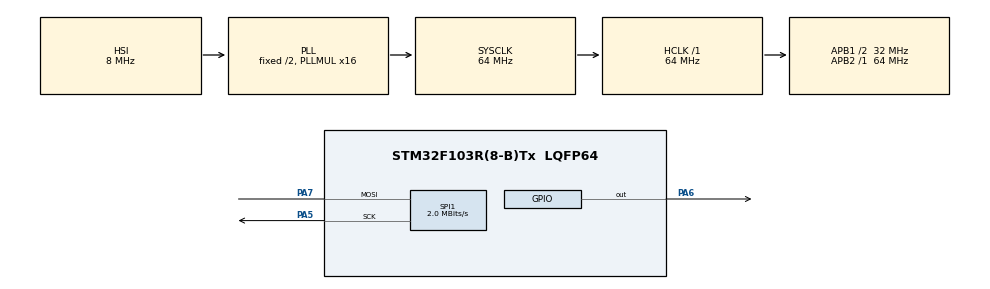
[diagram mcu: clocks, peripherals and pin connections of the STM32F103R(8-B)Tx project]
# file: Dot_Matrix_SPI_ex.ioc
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Mcu.Family=STM32F1
Mcu.Name=STM32F103R(8-B)Tx
Mcu.Package=LQFP64
NVIC.PriorityGroup=NVIC_PRIORITYGROUP_4
PA5.Mode=Simplex_Bidirectional_Master
PA5.Signal=SPI1_SCK
PA6.Signal=GPIO_Output
PA7.Mode=Simplex_Bidirectional_Master
PA7.Signal=SPI1_MOSI
ProjectManager.HeapSize=0x200
ProjectManager.StackSize=0x400
ProjectManager.TargetToolchain=CMake
RCC.AHBFreq_Value=64000000
RCC.APB1CLKDivider=RCC_HCLK_DIV2
RCC.APB1Freq_Value=32000000
RCC.APB1TimFreq_Value=64000000
RCC.APB2Freq_Value=64000000
RCC.APB2TimFreq_Value=64000000
RCC.HCLKFreq_Value=64000000
RCC.PLLMUL=RCC_PLL_MUL16
RCC.SYSCLKFreq_VALUE=64000000
RCC.SYSCLKSource=RCC_SYSCLKSOURCE_PLLCLK
RCC.USBFreq_Value=64000000
SPI1.BaudRatePrescaler=SPI_BAUDRATEPRESCALER_32
SPI1.CLKPolarity=SPI_POLARITY_HIGH
SPI1.CRCCalculation=SPI_CRCCALCULATION_DISABLE
SPI1.CalculateBaudRate=2.0 MBits/s
SPI1.DataSize=SPI_DATASIZE_16BIT
SPI1.Direction=SPI_DIRECTION_1LINE
SPI1.Mode=SPI_MODE_MASTER
SPI1.VirtualType=VM_MASTER
VP_SYS_VS_ND.Mode=No_Debug
board=custom

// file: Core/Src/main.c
/* USER CODE BEGIN Header */
/**
 ******************************************************************************
 * @file           : main.c
 * @brief          : Main program body
 ******************************************************************************
 * @attention
 *
 * Copyright (c) 2025 STMicroelectronics.
 * All rights reserved.
 *
 * This software is licensed under terms that can be found in the LICENSE file
 * in the root directory of this software component.
 * If no LICENSE file comes with this software, it is provided AS-IS.
 *
 ******************************************************************************
 */
/* USER CODE END Header */
#include "main.h"

/* USER CODE BEGIN Includes */
#include "matrix.h"
/* USER CODE END Includes */

SPI_HandleTypeDef hspi1;

void SystemClock_Config(void);
static void MX_GPIO_Init(void);
static void MX_SPI1_Init(void);

int main(void) {

    /* MCU
     * Configuration--------------------------------------------------------*/

    /* Reset of all peripherals, Initializes the Flash interface and the
     * Systick. */
    HAL_Init();

    /* Configure the system clock */
    SystemClock_Config();

    /* Initialize all configured peripherals */
    MX_GPIO_Init();
    MX_SPI1_Init();
    /* USER CODE BEGIN 2 */
    /**
     * MAX7219의 레지스터
     * - Shutdown reg.
     * - Mode reg.
     * - Intensity reg.
     * - Scan reg.
     * - Display-test reg.
     * ------------------------------------------------------------
     * On initial power-up, all control registers are reset, the
     * display is blanked, and the MAX7219/MAX7221 enter
     * shutdown mode. Program the display driver prior to
     * display use. Otherwise, it will initially be set to scan one
     * digit, it will not decode data in the data registers, and
     * the intensity register will be set to its minimum value.
     * ------------------------------------------------------------
     * 1. 파워가 연결되면 모든 레지스터(위에 적은 것들)가 초기화 된다.
     * 2. 먼저 셧다운 모드로 설정된다.
     * 3. 1개의 digit만 스캔하는 모드로 설정된다.
     * 4. 밝기 레지스터도 최소로 설정된다.
     * ------------------------------------------------------------
     * When no-decode is selected, data bits D7–D0 correspond to
     *  the segment lines of the MAX7219/MAX7221.
     * Table 6 shows the one-to-one pairing of each data bit
     * to the appropriate segment line.
     * ------------------------------------------------------------
     * 문서가 8-digit LED에 맞추어 작성되어 있다.
     * Table.5를 참고하면, D7~D0과 SegA~SegG핀의 값에 따라 7-segment의
     *  어떤 LED가 켜지는지 알 수 있다. 본래 기능대로라면 Digit Driver에서
     *  LED가 나타낼 정수값이, Segment Driver에서는 그 정수값을 표현하기
     *  위해 어떤 Segment가 켜지는지 출력된다.
     * 8x8 매트릭스를 위해서는 no-decode 모드로 설정해야한다.
     * no-decode 모드는 Digit Driver와 Segment Driver에 출력될 값이
     *  DIN(SPI의 MOSI)으로 전달된 데이터값이다. 디코드 되지 않고 곧바로
     *  출력된다.
     * 왜 Digit Driver가 매트릭스의 행이고 Segment Driver가
     *  매트릭스의 열인지 모르겠다. 매트릭스의 데이터 시트에 내용이 부족해
     *  이유를 정확히 알지 못했다.
     * ------------------------------------------------------------
     */
    LED_Matrix_Init(&hspi1);
    /* USER CODE END 2 */

    /* Infinite loop */
    /* USER CODE BEGIN WHILE */
    LED_Matrix_Clear(&hspi1);
    uint8_t matrix[8] = {0b11111111, 0b00000001, 0b00000001, 0b00000001,
                         0b00000001, 0b11110001, 0b00000001, 0b00001111};

    LED_Matrix_Print(&hspi1, matrix);

    while (1) {
        /* USER CODE END WHILE */

    }
}

void SystemClock_Config(void) {
    RCC_OscInitTypeDef RCC_OscInitStruct = {0};
    RCC_ClkInitTypeDef RCC_ClkInitStruct = {0};

    /** Initializes the RCC Oscillators according to the specified parameters
     * in the RCC_OscInitTypeDef structure.
     */
    RCC_OscInitStruct.OscillatorType = RCC_OSCILLATORTYPE_HSI;
    RCC_OscInitStruct.HSIState = RCC_HSI_ON;
    RCC_OscInitStruct.HSICalibrationValue = RCC_HSICALIBRATION_DEFAULT;
    RCC_OscInitStruct.PLL.PLLState = RCC_PLL_ON;
    RCC_OscInitStruct.PLL.PLLSource = RCC_PLLSOURCE_HSI_DIV2;
    RCC_OscInitStruct.PLL.PLLMUL = RCC_PLL_MUL16;
    if (HAL_RCC_OscConfig(&RCC_OscInitStruct) != HAL_OK) {
        Error_Handler();
    }

    /** Initializes the CPU, AHB and APB buses clocks
     */
    RCC_ClkInitStruct.ClockType = RCC_CLOCKTYPE_HCLK | RCC_CLOCKTYPE_SYSCLK |
                                  RCC_CLOCKTYPE_PCLK1 | RCC_CLOCKTYPE_PCLK2;
    RCC_ClkInitStruct.SYSCLKSource = RCC_SYSCLKSOURCE_PLLCLK;
    RCC_ClkInitStruct.AHBCLKDivider = RCC_SYSCLK_DIV1;
    RCC_ClkInitStruct.APB1CLKDivider = RCC_HCLK_DIV2;
    RCC_ClkInitStruct.APB2CLKDivider = RCC_HCLK_DIV1;

    if (HAL_RCC_ClockConfig(&RCC_ClkInitStruct, FLASH_LATENCY_2) != HAL_OK) {
        Error_Handler();
    }
}

static void MX_SPI1_Init(void) {

    /* SPI1 parameter configuration*/
    hspi1.Instance = SPI1;
    hspi1.Init.Mode = SPI_MODE_MASTER;
    hspi1.Init.Direction = SPI_DIRECTION_1LINE;
    hspi1.Init.DataSize = SPI_DATASIZE_16BIT;
    hspi1.Init.CLKPolarity = SPI_POLARITY_HIGH;
    hspi1.Init.CLKPhase = SPI_PHASE_1EDGE;
    hspi1.Init.NSS = SPI_NSS_SOFT;
    hspi1.Init.BaudRatePrescaler = SPI_BAUDRATEPRESCALER_32;
    hspi1.Init.FirstBit = SPI_FIRSTBIT_MSB;
    hspi1.Init.TIMode = SPI_TIMODE_DISABLE;
    hspi1.Init.CRCCalculation = SPI_CRCCALCULATION_DISABLE;
    hspi1.Init.CRCPolynomial = 10;
    if (HAL_SPI_Init(&hspi1) != HAL_OK) {
        Error_Handler();
    }
}

static void MX_GPIO_Init(void) {
    GPIO_InitTypeDef GPIO_InitStruct = {0};

    /* GPIO Ports Clock Enable */
    __HAL_RCC_GPIOA_CLK_ENABLE();

    /*Configure GPIO pin Output Level */
    HAL_GPIO_WritePin(GPIOA, GPIO_PIN_6, GPIO_PIN_RESET);

    /*Configure GPIO pin : PA6 */
    GPIO_InitStruct.Pin = GPIO_PIN_6;
    GPIO_InitStruct.Mode = GPIO_MODE_OUTPUT_PP;
    GPIO_InitStruct.Pull = GPIO_NOPULL;
    GPIO_InitStruct.Speed = GPIO_SPEED_FREQ_LOW;
    HAL_GPIO_Init(GPIOA, &GPIO_InitStruct);

}

void Error_Handler(void) {
    /* USER CODE BEGIN Error_Handler_Debug */
    /* User can add his own implementation to report the HAL error return state
     */
    __disable_irq();
    while (1) {
    }
    /* USER CODE END Error_Handler_Debug */
}

#ifdef USE_FULL_ASSERT
/**
 * @brief  Reports the name of the source file and the source line number
 *         where the assert_param error has occurred.
 * @param  file: pointer to the source file name
 * @param  line: assert_param error line source number
 * @retval None
 */
void assert_failed(uint8_t *file, uint32_t line) {
    /* USER CODE BEGIN 6 */
    /* User can add his own implementation to report the file name and line
       number, ex: printf("Wrong parameters value: file %s on line %d\r\n",
       file, line) */
    /* USER CODE END 6 */
}
#endif /* USE_FULL_ASSERT */
